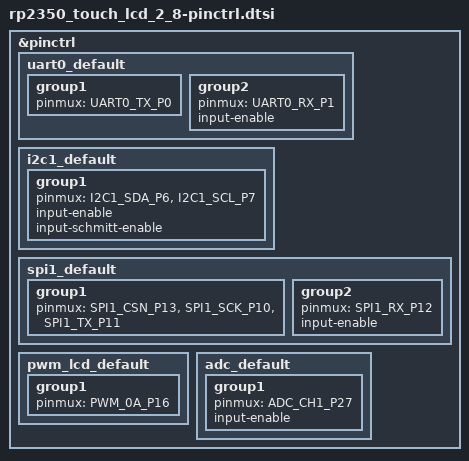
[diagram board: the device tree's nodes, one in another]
/*
 * Copyright (c) 2025 Your Name
 * SPDX-License-Identifier: Apache-2.0
 */

#include <zephyr/dt-bindings/pinctrl/rpi-pico-rp2350a-pinctrl.h>

&pinctrl {
	/* UART0 - Console */
	uart0_default: uart0_default {
		group1 {
			pinmux = <UART0_TX_P0>;
		};

		group2 {
			pinmux = <UART0_RX_P1>;
			input-enable;
		};
	};

	/* I2C1 - Touch controller and IMU */
	i2c1_default: i2c1_default {
		group1 {
			pinmux = <I2C1_SDA_P6>, <I2C1_SCL_P7>;
			input-enable;
			input-schmitt-enable;
		};
	};

	/* SPI1 - LCD Display */
	spi1_default: spi1_default {
		group1 {
			pinmux = <SPI1_CSN_P13>, <SPI1_SCK_P10>, <SPI1_TX_P11>;
		};

		group2 {
			pinmux = <SPI1_RX_P12>;
			input-enable;
		};
	};

	/* PWM for LCD backlight on GPIO16 */
	pwm_lcd_default: pwm_lcd_default {
		group1 {
			pinmux = <PWM_0A_P16>;
		};
	};

	/* ADC for battery voltage on GPIO27 */
	adc_default: adc_default {
		group1 {
			pinmux = <ADC_CH1_P27>;
			input-enable;
		};
	};
};
